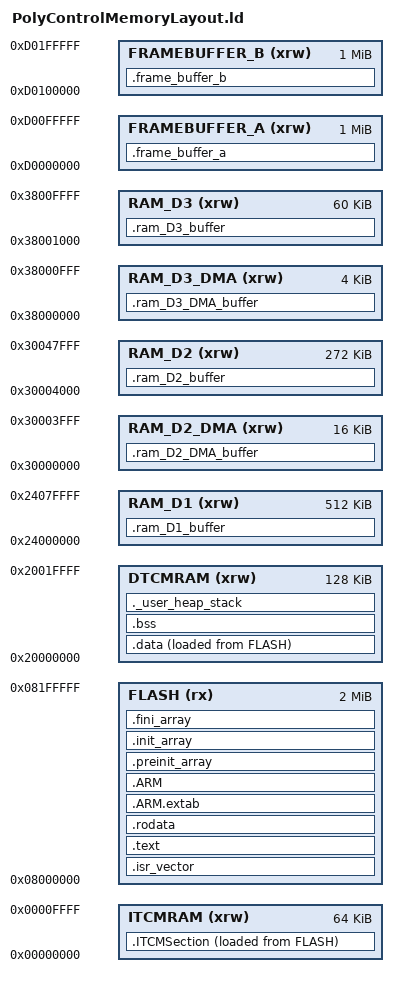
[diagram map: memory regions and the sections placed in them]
/*
******************************************************************************
**

**  File        : LinkerScript.ld
**
**  Author		: Auto-generated by System Workbench for STM32
**
**  Abstract    : Linker script for STM32H743ZITx series
**                2048Kbytes FLASH and 1056Kbytes RAM
**
**                Set heap size, stack size and stack location according
**                to application requirements.
**
**                Set memory bank area and size if external memory is used.
**
**  Target      : STMicroelectronics STM32
**
**  Distribution: The file is distributed “as is,” without any warranty
**                of any kind.
**
*****************************************************************************
** @attention
**
** <h2><center>&copy; COPYRIGHT(c) 2019 STMicroelectronics</center></h2>
**
** Redistribution and use in source and binary forms, with or without modification,
** are permitted provided that the following conditions are met:
**   1. Redistributions of source code must retain the above copyright notice,
**      this list of conditions and the following disclaimer.
**   2. Redistributions in binary form must reproduce the above copyright notice,
**      this list of conditions and the following disclaimer in the documentation
**      and/or other materials provided with the distribution.
**   3. Neither the name of STMicroelectronics nor the names of its contributors
**      may be used to endorse or promote products derived from this software
**      without specific prior written permission.
**
** THIS SOFTWARE IS PROVIDED BY THE COPYRIGHT HOLDERS AND CONTRIBUTORS "AS IS"
** AND ANY EXPRESS OR IMPLIED WARRANTIES, INCLUDING, BUT NOT LIMITED TO, THE
** IMPLIED WARRANTIES OF MERCHANTABILITY AND FITNESS FOR A PARTICULAR PURPOSE ARE
** DISCLAIMED. IN NO EVENT SHALL THE COPYRIGHT HOLDER OR CONTRIBUTORS BE LIABLE
** FOR ANY DIRECT, INDIRECT, INCIDENTAL, SPECIAL, EXEMPLARY, OR CONSEQUENTIAL
** DAMAGES (INCLUDING, BUT NOT LIMITED TO, PROCUREMENT OF SUBSTITUTE GOODS OR
** SERVICES; LOSS OF USE, DATA, OR PROFITS; OR BUSINESS INTERRUPTION) HOWEVER
** CAUSED AND ON ANY THEORY OF LIABILITY, WHETHER IN CONTRACT, STRICT LIABILITY,
** OR TORT (INCLUDING NEGLIGENCE OR OTHERWISE) ARISING IN ANY WAY OUT OF THE USE
** OF THIS SOFTWARE, EVEN IF ADVISED OF THE POSSIBILITY OF SUCH DAMAGE.
**
*****************************************************************************
*/

/* Entry Point */
ENTRY(Reset_Handler)

/* Highest address of the user mode stack */
_estack = 0x20020000;    /* end of RAM */
/* Generate a link error if heap and stack don't fit into RAM */
_Min_Heap_Size = 0x200;      /* required amount of heap  */
_Min_Stack_Size = 0x400; /* required amount of stack */

/* Specify the memory areas */
MEMORY
{
DTCMRAM (xrw)      : ORIGIN = 0x20000000, LENGTH = 128K
RAM_D1 (xrw)      : ORIGIN = 0x24000000, LENGTH = 512K
RAM_D2_DMA (xrw)      : ORIGIN = 0x30000000, LENGTH = 16K
RAM_D2 (xrw)      : ORIGIN = 0x30004000, LENGTH = 272K
RAM_D3_DMA (xrw)      : ORIGIN = 0x38000000, LENGTH = 4K
RAM_D3 (xrw)      : ORIGIN = 0x38001000, LENGTH = 60K
FRAMEBUFFER_A (xrw)      : ORIGIN = 0xD0000000, LENGTH = 1024K
FRAMEBUFFER_B (xrw)      : ORIGIN = 0xD0100000, LENGTH = 1024K
ITCMRAM (xrw)      : ORIGIN = 0x00000000, LENGTH = 64K
FLASH (rx)      : ORIGIN = 0x8000000, LENGTH = 2048K
}

/* Define output sections */
SECTIONS
{
  /* The startup code goes first into FLASH */
  .isr_vector :
  {
    . = ALIGN(4);
    KEEP(*(.isr_vector)) /* Startup code */
    . = ALIGN(4);
  } >FLASH

  _siITCM = LOADADDR(.ITCMSection);

  .ITCMSection :
  {
 
    . = ALIGN(4);
    _sITCM = .;      

    /* *gfx* (.text .text*) */
    *guiBase* (.text .text*)
    *datacore* (.text .text*)
    *polyMath.o (.text .text*)
    *layer* (.text .text*)
    *hid* (.text .text*)
    *flagHandler.o (.text .text*) 
    *com* (.text .text*) 
    *stm32h7xx_it.o (.text .text*)
    *arp.o (.text .text*)
    *clock.o (.text .text*)
    *liveData.o (.text .text*)
    *liveDataBase.o (.text .text*)
    *voiceHandler.o (.text .text*)
    *IS31FL3216.o (.text .text*)
    *MAX11128.o (.text .text*)
    *rotary.o (.text .text*)
    *bus.o (.text .text*)
    *busInterface.o (.text .text*)
    *stm32h7xx_hal_dma2d.o (.text .text*)
    *guiPanelEffect.o (.text .text*)
    *polyControlIRQ.o (.text .text*)
    *usbd_midi_if.o (.text .text*)


    /* *gfx* (.rodata .rodata*)  */
    *polyMath.o (.rodata .rodata*) 
    *flagHandler.o (.rodata .rodata*) 
    *stm32h7xx_it.o (.rodata .rodata*) 
    *arp.o (.rodata .rodata*)
    *clock.o (.rodata .rodata*)
    *liveData.o (.rodata .rodata*)
    *liveDataBase.o (.rodata .rodata*)
    *voiceHandler.o (.rodata .rodata*)
    *rotary.o (.rodata .rodata*)
    *bus.o (.rodata .rodata*)
    *busInterface.o (.rodata .rodata*)
    *device.o (.rodata .rodata*)
    *polyControlIRQ.o (.rodata .rodata*)
    *usbd_midi_if.o (.rodata .rodata*)

    . = ALIGN(4); 
    _eITCM = .;        
   
  } >ITCMRAM AT> FLASH


  /* The program code and other data goes into FLASH */
  .text :
  {
    . = ALIGN(4);
    *(.text)           /* .text sections (code) */
    *(.text*)          /* .text* sections (code) */
    *(.glue_7)         /* glue arm to thumb code */
    *(.glue_7t)        /* glue thumb to arm code */
    *(.eh_frame)

    KEEP (*(.init))
    KEEP (*(.fini))

    . = ALIGN(4);
    _etext = .;        /* define a global symbols at end of code */
  } >FLASH

  /* Constant data goes into FLASH */
  .rodata :
  {
    . = ALIGN(4);
    *(.rodata)         /* .rodata sections (constants, strings, etc.) */
    *(.rodata*)        /* .rodata* sections (constants, strings, etc.) */
    . = ALIGN(4);
  } >FLASH

  .ARM.extab   : { *(.ARM.extab* .gnu.linkonce.armextab.*) } >FLASH
  .ARM : {
    __exidx_start = .;
    *(.ARM.exidx*)
    __exidx_end = .;
  } >FLASH

  .preinit_array     :
  {
    PROVIDE_HIDDEN (__preinit_array_start = .);
    KEEP (*(.preinit_array*))
    PROVIDE_HIDDEN (__preinit_array_end = .);
  } >FLASH
  .init_array :
  {
    PROVIDE_HIDDEN (__init_array_start = .);
    KEEP (*(SORT(.init_array.*)))
    KEEP (*(.init_array*))
    PROVIDE_HIDDEN (__init_array_end = .);
  } >FLASH
  .fini_array :
  {
    PROVIDE_HIDDEN (__fini_array_start = .);
    KEEP (*(SORT(.fini_array.*)))
    KEEP (*(.fini_array*))
    PROVIDE_HIDDEN (__fini_array_end = .);
  } >FLASH

  /* used by the startup to initialize data */
  _sidata = LOADADDR(.data);

  /* Initialized data sections goes into RAM, load LMA copy after code */
  .data : 
  {
    . = ALIGN(4);
    _sdata = .;        /* create a global symbol at data start */
    *(.data)           /* .data sections */
    *(.data*)          /* .data* sections */

    . = ALIGN(4);
    _edata = .;        /* define a global symbol at data end */
  } >DTCMRAM AT> FLASH

  
  /* Uninitialized data section */
  . = ALIGN(4);
  .bss :
  {
    /* This is used by the startup in order to initialize the .bss secion */
    _sbss = .;         /* define a global symbol at bss start */
    __bss_start__ = _sbss;
    *(.bss)
    *(.bss*)
    *(COMMON)

    . = ALIGN(4);
    _ebss = .;         /* define a global symbol at bss end */
    __bss_end__ = _ebss;
  } >DTCMRAM

  /* User_heap_stack section, used to check that there is enough RAM left */
  ._user_heap_stack :
  {
    . = ALIGN(8);
    PROVIDE ( end = . );
    PROVIDE ( _end = . );
    . = . + _Min_Heap_Size;
    . = . + _Min_Stack_Size;
    . = ALIGN(8);
  } >DTCMRAM

  

  /* Remove information from the standard libraries */
  /DISCARD/ :
  {
    libc.a ( * )
    libm.a ( * )
    libgcc.a ( * )
  }

  .ARM.attributes 0 : { *(.ARM.attributes) }


  .ram_D1_buffer : /* Space before ':' is critical */
  {
    *(.ram_D1_buffer)
  } >RAM_D1

  .ram_D2_buffer : /* Space before ':' is critical */
  {
    *(.ram_D2_buffer)
  } >RAM_D2

    .ram_D2_DMA_buffer : /* Space before ':' is critical */
  {
    *(.ram_D2_DMA_buffer)
  } >RAM_D2_DMA

  .ram_D3_buffer : /* Space before ':' is critical */
  {
    *(.ram_D3_buffer)
  } >RAM_D3

    .ram_D3_DMA_buffer : /* Space before ':' is critical */
  {
    *(.ram_D3_DMA_buffer)
  } >RAM_D3_DMA  

  .frame_buffer_a : /* Space before ':' is critical */
  {
    *(.frame_buffer_a)
  } >FRAMEBUFFER_A

    .frame_buffer_b : /* Space before ':' is critical */
  {
    *(.frame_buffer_b)
  } >FRAMEBUFFER_B
  
}


